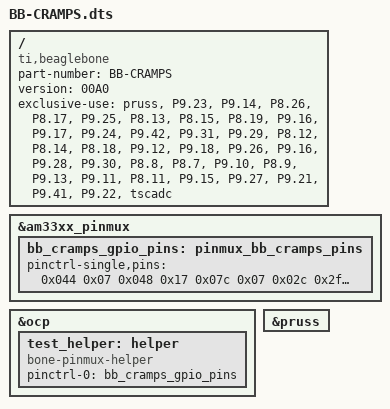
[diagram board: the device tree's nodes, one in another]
/*
 * Based on github.com/jadonk/validation-scripts/tree/master/test-capemgr
 * Copyright (C) 2012 Texas Instruments Incorporated - http://www.ti.com/
 *
 * This program is free software; you can redistribute it and/or modify
 * it under the terms of the GNU General Purpose License Version 2 as
 * published by the Free Software Foundation
 *
 * To create the binary representation that the device manager can handle, run
 * make BB-CRAMPS-00A0.dtbo
 * See bb-cramps-cape-pinmux.sh how to enable.
 */

/dts-v1/;
/plugin/;

/{
    compatible = "ti,beaglebone", "ti,beaglebone-black", "ti,beaglebone-green";
    part-number = "BB-CRAMPS";  /* CRAMPS Cape */
    version = "00A0";

    exclusive-use = "pruss",  // Programmable realtime unit
		  "P9.23", "P9.14", "P8.26", "P8.17", "P9.25",						// power control
		  "P8.13", "P8.15", "P8.19", "P9.16", "P9.17", "P9.24", "P9.42", "P9.31", "P9.29",	// step
		  "P8.12", "P8.14", "P8.18", "P9.12", "P9.18", "P9.26", "P9.16", "P9.28", "P9.30",	// direction
		  "P8.8", "P8.7", "P9.10", "P8.9", "P9.13", "P9.11",					// endstops
		  "P8.11", "P9.15", "P9.27", "P9.21", "P9.41", "P9.22",				        // fets
		  "tscadc";   // Analog digital converter

    fragment@0 {
        target = <&am33xx_pinmux>;
        __overlay__ {
            bb_cramps_gpio_pins: pinmux_bb_cramps_pins {
                pinctrl-single,pins = <
				/* P9.9   Power Button */
				/* P9.10  Reset Button */
		    0x044 0x07	/* P9.23  GPIO1_17 output, pulldown  machine_pwr */
		    0x048 0x17	/* P9.14  GPIO1_18 output, pullup    all_stepper enable_pin */
		    0x07c 0x07	/* P8.26  GPIO1_29 output, pulldown  estop_sw */
		    0x02c 0x2f	/* P8.17  GPIO0_27 input             estop */
		    0x1ac 0x07	/* P9.25  GPIO3_21 output, pulldown  led */

		    0x024 0x07	/* P8.13  GPIO0_23 output, pulldown  stepper_x	step_pin */
		    0x03c 0x07	/* P8.15  GPIO1_15 output, pulldown  stepper_y	step_pin */
		    0x020 0x07	/* P8.19  GPIO0_22 output, pulldown  stepper_z	step_pin */
		    0x04c 0x07	/* P9.16  GPIO1_19 output, pulldown  extruder(0) step_pin */
		    0x15c 0x07	/* P9.17  GPIO0_5  output, pulldown  extruder(1) step_pin */
		    0x184 0x07	/* P9.24  GPIO0_15 output, pulldown  extruder(2) step_pin */
		    
		    0x030 0x07	/* P8.12  GPIO1_12 output, pulldown  stepper_x dir_pin */
		    0x028 0x07	/* P8.14  GPIO0_26 output, pulldown  stepper_y dir_pin */
		    0x08c 0x07	/* P8.18  GPIO2_1  output, pulldown  stepper_z dir_pin */
		    0x078 0x07	/* P9.12  GPIO1_28 output, pulldown  extruder(0) dir_pin */
		    0x158 0x07	/* P9.18  GPIO0_4  output, pulldown  extruder(1) dir_pin */
		    0x180 0x07	/* P9.26  GPIO0_14 output, pulldown  extruder(2) dir_pin */
		    
		    0x094 0x37	/* P8.8   GPIO2_3  input, pullup     stepper_x endstop_pin (min) */
		    0x090 0x37	/* P8.7   GPIO2_2  input, pullup     stepper_x endstop_pin (max) */
		    0x098 0x37	/* P8.10  GPIO2_4  input, pullup     stepper_y endstop_pin (min) */
		    0x09c 0x37	/* P8.9   GPIO2_5  input, pullup     stepper_y endstop_pin (max) */
		    0x074 0x37	/* P9.13  GPIO0_31 input, pullup     stepper_z endstop_pin (min) */
		    0x070 0x37	/* P9.11  GPIO0_30 input, pullup     stepper_z endstop_pin (max) */

		    0x034 0x07	/* P8.11  GPIO1_13 output, pulldown  heat_bed heater_pin */
		    0x040 0x07	/* P9.15  GPIO1_16 output, pulldown  extruder(0) heater_pin */
		    0x1a4 0x07	/* P9.27  GPIO3_19 output, pulldown  extruder(1) heater_pin */
		    0x154 0x07	/* P9.21  GPIO0_3  output, pulldown  extruder(2) heater_pin */
		    0x1b4 0x07	/* P9.41  GPIO0_20 output, pulldown  fan1 */
		    0x150 0x07	/* P9.22  GPIO0_2  output, pulldown  fan2 */

				/* P9.20  GPIO0_12          sda */
				/* P9.19  GPIO0_13          scl */

				/* P9.31  GPIO3_14          sck */
				/* P9.29  GPIO3_15          miso */
				/* P9.30  GPIO3_16          mosi */
				/* P9.28  GPIO3_17          spi_cs0 */

				/* P9.33  AIN4               head_bed sensor_pin (thermistor 0) */
				/* P9.35  AIN6               thermistor 2 */
				/* P9.36  AIN5               extruder(0) sensor_pin (thermistor 1) */
				/* P9.37  AIN2               ain2 */
				/* P9.38  AIN3               ain3 */
				/* P9.39  AIN0               ain0 */
				/* P9.40  AIN1               ain1 */
                >;
            };
        };
    };

   fragment@1 {
        target = <&ocp>;
        __overlay__ {
            test_helper: helper {
                compatible = "bone-pinmux-helper";
                pinctrl-names = "default";
                pinctrl-0 = <&bb_cramps_gpio_pins>;
                status = "okay";
            };
        };
    };

   fragment@2{
        target = <&pruss>;
        __overlay__ {
            status = "okay";
        };
   };
};
